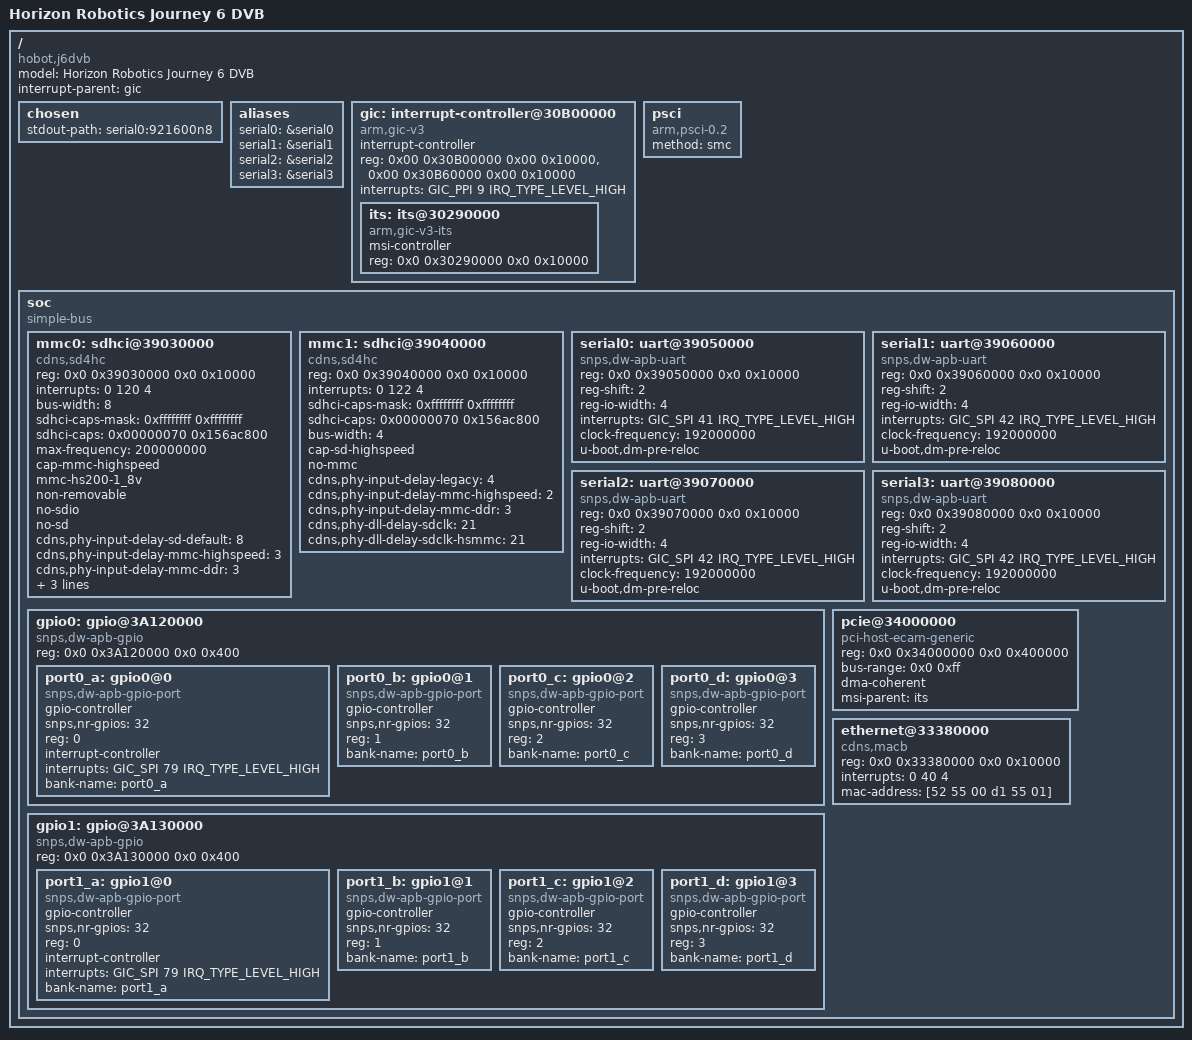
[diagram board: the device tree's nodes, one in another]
// SPDX-License-Identifier: GPL-2.0+
/*
 * Horizon Robotics J6 DVB device tree
 *
 * Copyright (C) 2023 Horizon Robotics Co,.Ltd.
 */

/dts-v1/;
#include <dt-bindings/interrupt-controller/arm-gic.h>

/ {
	model = "Horizon Robotics Journey 6 DVB";
	compatible = "hobot,j6dvb";
	#address-cells = <2>;
	#size-cells = <2>;
	interrupt-parent = <&gic>;

	chosen {
		stdout-path = "serial0:921600n8";
	};

	aliases {
		serial0 = &serial0;
		serial1 = &serial1;
		serial2 = &serial2;
		serial3 = &serial3;
	};

	gic: interrupt-controller@30B00000 {
		compatible = "arm,gic-v3";
		#interrupt-cells = <3>;
		#address-cells = <2>;
		#size-cells = <2>;
		interrupt-controller;
		reg = <0x00 0x30B00000 0x00 0x10000>,
			<0x00 0x30B60000 0x00 0x10000>;
		interrupts = <GIC_PPI 9 IRQ_TYPE_LEVEL_HIGH>;
		its: its@30290000 {
			compatible = "arm,gic-v3-its";
			msi-controller;
			reg = <0x0 0x30290000 0x0 0x10000>;
		};
	};

	psci {
		compatible = "arm,psci-0.2";
		method = "smc";
	};

	soc {
		compatible = "simple-bus";
		#address-cells = <2>;
		#size-cells = <2>;
		ranges;

		mmc0: sdhci@39030000 {
			compatible = "cdns,sd4hc";
			reg = <0x0 0x39030000 0x0 0x10000>;
			interrupts = <0 120 4>;
			bus-width = <8>;
			sdhci-caps-mask = <0xffffffff 0xffffffff>;
			sdhci-caps = <0x00000070 0x156ac800>;	// for 3.3V SD
			//sdhci-caps = <0x00000070 0x546ec800>;	// for 1.8V eMMC
			max-frequency = <200000000>;
			cap-mmc-highspeed;
			mmc-hs200-1_8v;
			non-removable;
			no-sdio;
			no-sd;
			cdns,phy-input-delay-sd-default = <8>;
			cdns,phy-input-delay-mmc-highspeed = <3>;
			cdns,phy-input-delay-mmc-ddr = <3>;
			cdns,phy-dll-delay-strobe = <33>; /* for hs400 */
			cdns,phy-dll-delay-sdclk = <45>;
			cdns,phy-dll-delay-sdclk-hsmmc = <45>; /* golden for hs400 */
			status = "okay";
		};

		mmc1: sdhci@39040000 {
			compatible = "cdns,sd4hc";
			reg = <0x0 0x39040000 0x0 0x10000>;
			interrupts = <0 122 4>;
			sdhci-caps-mask = <0xffffffff 0xffffffff>;
			sdhci-caps = <0x00000070 0x156ac800>;	// for 3.3V SD
			//sdhci-caps = <0x00000070 0x546ec800>;	// for 1.8V eMMC
			bus-width = <4>;
			cap-sd-highspeed;
			no-mmc;
			cdns,phy-input-delay-legacy = <4>;
			cdns,phy-input-delay-mmc-highspeed = <2>;
			cdns,phy-input-delay-mmc-ddr = <3>;
			cdns,phy-dll-delay-sdclk = <21>;
			cdns,phy-dll-delay-sdclk-hsmmc = <21>;
			status = "okay";
		};

		serial0: uart@39050000 {
			compatible = "snps,dw-apb-uart";
			reg = <0x0 0x39050000 0x0 0x10000>;
			reg-shift = <2>;
			reg-io-width = <4>;
			interrupts = <GIC_SPI 41 IRQ_TYPE_LEVEL_HIGH>;
			clock-frequency = <192000000>; //192MHz
			u-boot,dm-pre-reloc;
			status = "okay";
		};

		serial1: uart@39060000 {
			compatible = "snps,dw-apb-uart";
			reg = <0x0 0x39060000 0x0 0x10000>;
			reg-shift = <2>;
			reg-io-width = <4>;
			interrupts = <GIC_SPI 42 IRQ_TYPE_LEVEL_HIGH>;
			clock-frequency = <192000000>;
			u-boot,dm-pre-reloc;
			status = "okay";
		};

		serial2: uart@39070000 {
			compatible = "snps,dw-apb-uart";
			reg = <0x0 0x39070000 0x0 0x10000>;
			reg-shift = <2>;
			reg-io-width = <4>;
			interrupts = <GIC_SPI 42 IRQ_TYPE_LEVEL_HIGH>;
			clock-frequency = <192000000>;
			u-boot,dm-pre-reloc;
			status = "okay";
		};

		serial3: uart@39080000 {
			compatible = "snps,dw-apb-uart";
			reg = <0x0 0x39080000 0x0 0x10000>;
			reg-shift = <2>;
			reg-io-width = <4>;
			interrupts = <GIC_SPI 42 IRQ_TYPE_LEVEL_HIGH>;
			clock-frequency = <192000000>;
			u-boot,dm-pre-reloc;
			status = "okay";
		};

		gpio0: gpio@3A120000 {
			compatible = "snps,dw-apb-gpio";
			reg = <0x0 0x3A120000 0x0 0x400>;
			#address-cells = <1>;
			#size-cells = <0>;
			status = "okay";

			port0_a: gpio0@0 {
				compatible = "snps,dw-apb-gpio-port";
				gpio-controller;
				#gpio-cells = <2>;
				snps,nr-gpios = <32>;
				reg = <0>;
				interrupt-controller;
				#interrupt-cells = <2>;
				interrupts = <GIC_SPI 79 IRQ_TYPE_LEVEL_HIGH>;
				bank-name = "port0_a";
			};

			port0_b: gpio0@1 {
				compatible = "snps,dw-apb-gpio-port";
				gpio-controller;
				#gpio-cells = <2>;
				snps,nr-gpios = <32>;
				reg = <1>;
				bank-name = "port0_b";
			};

			port0_c: gpio0@2 {
				compatible = "snps,dw-apb-gpio-port";
				gpio-controller;
				#gpio-cells = <2>;
				snps,nr-gpios = <32>;
				reg = <2>;
				bank-name = "port0_c";
			};

			port0_d: gpio0@3 {
				compatible = "snps,dw-apb-gpio-port";
				gpio-controller;
				#gpio-cells = <2>;
				snps,nr-gpios = <32>;
				reg = <3>;
				bank-name = "port0_d";
			};
		};

		gpio1: gpio@3A130000 {
			compatible = "snps,dw-apb-gpio";
			reg = <0x0 0x3A130000 0x0 0x400>;
			#address-cells = <1>;
			#size-cells = <0>;
			status = "okay";

			port1_a: gpio1@0 {
				compatible = "snps,dw-apb-gpio-port";
				gpio-controller;
				#gpio-cells = <2>;
				snps,nr-gpios = <32>;
				reg = <0>;
				interrupt-controller;
				#interrupt-cells = <2>;
				interrupts = <GIC_SPI 79 IRQ_TYPE_LEVEL_HIGH>;
				bank-name = "port1_a";
			};

			port1_b: gpio1@1 {
				compatible = "snps,dw-apb-gpio-port";
				gpio-controller;
				#gpio-cells = <2>;
				snps,nr-gpios = <32>;
				reg = <1>;
				bank-name = "port1_b";
			};

			port1_c: gpio1@2 {
				compatible = "snps,dw-apb-gpio-port";
				gpio-controller;
				#gpio-cells = <2>;
				snps,nr-gpios = <32>;
				reg = <2>;
				bank-name = "port1_c";
			};

			port1_d: gpio1@3 {
				compatible = "snps,dw-apb-gpio-port";
				gpio-controller;
				#gpio-cells = <2>;
				snps,nr-gpios = <32>;
				reg = <3>;
				bank-name = "port1_d";
			};
		};

		pcie@34000000 {
			compatible = "pci-host-ecam-generic";
			device_type = "pci";
			reg = <0x0 0x34000000 0x0 0x400000>;
			#address-cells = <3>;
			#size-cells = <2>;
			ranges = <0x02000000 0 0x80000000 0 0x80000000 0 0x40000000
						0x03000000 0x80 0x00000000 0x80 0x00000000 0x80 0x00000000>;
			bus-range = <0x0 0xff>;
			dma-coherent;
			#interrupt-cells = <1>;
			msi-parent = <&its>;
			status = "okay";
		};

		ethernet@33380000 {
			compatible = "cdns,macb";
			reg = <0x0 0x33380000 0x0 0x10000>;
			interrupts = <0 40 4>;
			mac-address = [52 55 00 d1 55 01];
			status = "okay";
		};
	};
};
